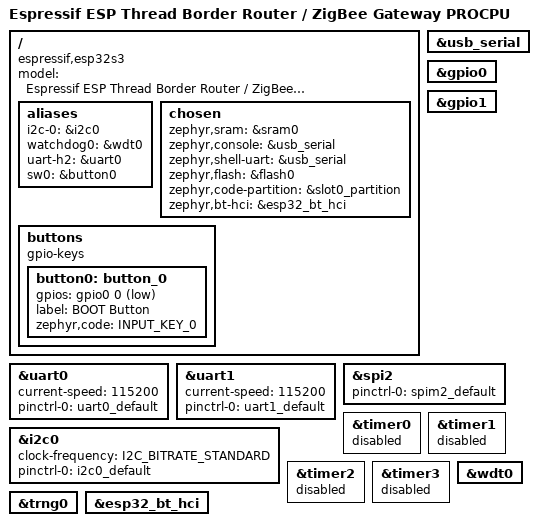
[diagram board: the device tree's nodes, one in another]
/*
 * Copyright (c) 2025 Espressif Systems (Shanghai) Co., Ltd.
 *
 * SPDX-License-Identifier: Apache-2.0
 */
/dts-v1/;

#include "espressif/esp32s3/esp32s3_wroom_n8.dtsi"
#include <zephyr/dt-bindings/input/input-event-codes.h>
#include <zephyr/dt-bindings/input/esp32-touch-sensor-input.h>
#include <espressif/partitions_0x0_amp_8M.dtsi>
#include "esp_threadbr_zigbeegw-pinctrl.dtsi"

/ {
	model = "Espressif ESP Thread Border Router / ZigBee Gateway PROCPU";
	compatible = "espressif,esp32s3";

	aliases {
		i2c-0 = &i2c0;
		watchdog0 = &wdt0;
	};

	chosen {
		zephyr,sram = &sram0;
		zephyr,console = &usb_serial;
		zephyr,shell-uart = &usb_serial;
		// zephyr,shell-uart = &uart0;
		// zephyr,console = &uart0;
		zephyr,flash = &flash0;
		zephyr,code-partition = &slot0_partition;
		zephyr,bt-hci = &esp32_bt_hci;
	};

	aliases {
		uart-h2 = &uart0;
		sw0 = &button0;
	};

	buttons {
		compatible = "gpio-keys";

		button0: button_0 {
			gpios = <&gpio0 0 (GPIO_PULL_UP | GPIO_ACTIVE_LOW)>;
			label = "BOOT Button";
			zephyr,code = <INPUT_KEY_0>;
		};
	};

//	h2 {
//		compatible = "gpio-leds";
//		h2_reset: h2_reset {
//			gpios = <&gpio0 7 GPIO_ACTIVE_LOW | GPIO_PULL_UP>;
//			label = "H2 Reset";
//		};
//		h2_boot: h2_boot {
//			gpios = <&gpio0 8 GPIO_ACTIVE_LOW | GPIO_PULL_UP>;
//			label = "H2 Boot";
//		};
//		h2_wl_active: h2_wl_active {
//			gpios = <&gpio0 8 GPIO_ACTIVE_LOW | GPIO_PULL_UP>;
//			label = "H2 Boot";
//		};
//		h2_bt_active: h2_bt_active {
//			gpios = <&gpio0 8 GPIO_ACTIVE_LOW | GPIO_PULL_UP>;
//			label = "H2 Boot";
//		};
//		h2_bt_priority: h2_wl_priority {
//			gpios = <&gpio0 8 GPIO_ACTIVE_LOW | GPIO_PULL_UP>;
//			label = "H2 Boot";
//		};
//	};
};

&usb_serial {
	status = "okay";
};

&uart0 {
	status = "okay";
	current-speed = <115200>;
	pinctrl-0 = <&uart0_default>;
	pinctrl-names = "default";
};

&uart1 {
	status = "okay";
	current-speed = <115200>;
	pinctrl-0 = <&uart1_default>;
	pinctrl-names = "default";
};

&gpio0 {
	status = "okay";
};

&gpio1 {
	status = "okay";
};

&i2c0 {
	clock-frequency = <I2C_BITRATE_STANDARD>;
	pinctrl-0 = <&i2c0_default>;
	pinctrl-names = "default";
};

&spi2 {
	#address-cells = <1>;
	#size-cells = <0>;
	status = "okay";
	pinctrl-0 = <&spim2_default>;
	pinctrl-names = "default";
};

&timer0 {
	status = "disabled";
};

&timer1 {
	status = "disabled";
};

&timer2 {
	status = "disabled";
};

&timer3 {
	status = "disabled";
};

&wdt0 {
	status = "okay";
};

&trng0 {
	status = "okay";
};

&esp32_bt_hci {
	status = "okay";
};
